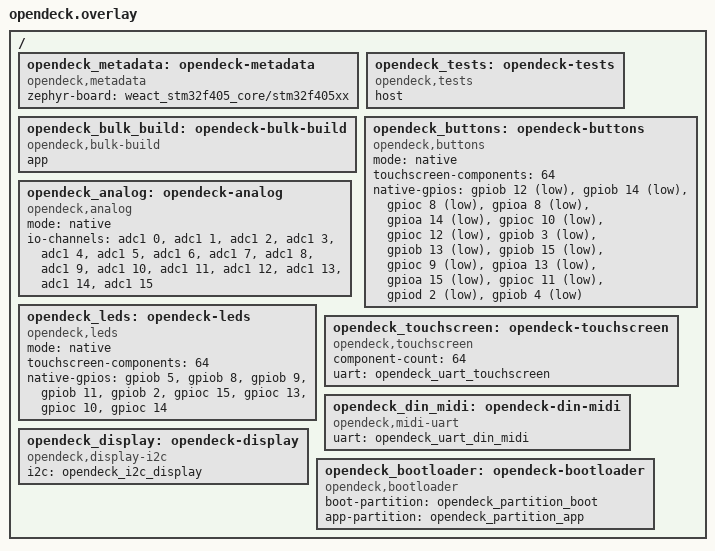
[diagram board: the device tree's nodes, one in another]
/ {
    opendeck_metadata: opendeck-metadata {
        compatible = "opendeck,metadata";
        zephyr-board = "weact_stm32f405_core/stm32f405xx";
    };

    opendeck_tests: opendeck-tests {
        compatible = "opendeck,tests";
        host;
    };

    opendeck_bulk_build: opendeck-bulk-build {
        compatible = "opendeck,bulk-build";
        app;
    };

    opendeck_buttons: opendeck-buttons {
        compatible = "opendeck,buttons";
        mode = "native";
        touchscreen-components = <64>;
        native-gpios =
            <&gpiob 12 (GPIO_PULL_UP | GPIO_ACTIVE_LOW)>,
            <&gpiob 14 (GPIO_PULL_UP | GPIO_ACTIVE_LOW)>,
            <&gpioc 8 (GPIO_PULL_UP | GPIO_ACTIVE_LOW)>,
            <&gpioa 8 (GPIO_PULL_UP | GPIO_ACTIVE_LOW)>,
            <&gpioa 14 (GPIO_PULL_UP | GPIO_ACTIVE_LOW)>,
            <&gpioc 10 (GPIO_PULL_UP | GPIO_ACTIVE_LOW)>,
            <&gpioc 12 (GPIO_PULL_UP | GPIO_ACTIVE_LOW)>,
            <&gpiob 3 (GPIO_PULL_UP | GPIO_ACTIVE_LOW)>,
            <&gpiob 13 (GPIO_PULL_UP | GPIO_ACTIVE_LOW)>,
            <&gpiob 15 (GPIO_PULL_UP | GPIO_ACTIVE_LOW)>,
            <&gpioc 9 (GPIO_PULL_UP | GPIO_ACTIVE_LOW)>,
            <&gpioa 13 (GPIO_PULL_UP | GPIO_ACTIVE_LOW)>,
            <&gpioa 15 (GPIO_PULL_UP | GPIO_ACTIVE_LOW)>,
            <&gpioc 11 (GPIO_PULL_UP | GPIO_ACTIVE_LOW)>,
            <&gpiod 2 (GPIO_PULL_UP | GPIO_ACTIVE_LOW)>,
            <&gpiob 4 (GPIO_PULL_UP | GPIO_ACTIVE_LOW)>;
    };

    opendeck_analog: opendeck-analog {
        compatible = "opendeck,analog";
        mode = "native";
        io-channels =
            <&adc1 0>,
            <&adc1 1>,
            <&adc1 2>,
            <&adc1 3>,
            <&adc1 4>,
            <&adc1 5>,
            <&adc1 6>,
            <&adc1 7>,
            <&adc1 8>,
            <&adc1 9>,
            <&adc1 10>,
            <&adc1 11>,
            <&adc1 12>,
            <&adc1 13>,
            <&adc1 14>,
            <&adc1 15>;
    };

    opendeck_leds: opendeck-leds {
        compatible = "opendeck,leds";
        mode = "native";
        touchscreen-components = <64>;
        native-gpios =
            <&gpiob 5 GPIO_ACTIVE_HIGH>,
            <&gpiob 8 GPIO_ACTIVE_HIGH>,
            <&gpiob 9 GPIO_ACTIVE_HIGH>,
            <&gpiob 11 GPIO_ACTIVE_HIGH>,
            <&gpiob 2 GPIO_ACTIVE_HIGH>,
            <&gpioc 15 GPIO_ACTIVE_HIGH>,
            <&gpioc 13 GPIO_ACTIVE_HIGH>,
            <&gpioc 10 GPIO_ACTIVE_HIGH>,
            <&gpioc 14 GPIO_ACTIVE_HIGH>;
    };

    opendeck_touchscreen: opendeck-touchscreen {
        compatible = "opendeck,touchscreen";
        component-count = <64>;
        uart = <&opendeck_uart_touchscreen>;
    };

    opendeck_din_midi: opendeck-din-midi {
        compatible = "opendeck,midi-uart";
        uart = <&opendeck_uart_din_midi>;
    };

    opendeck_display: opendeck-display {
        compatible = "opendeck,display-i2c";
        i2c = <&opendeck_i2c_display>;
    };

    opendeck_bootloader: opendeck-bootloader {
        compatible = "opendeck,bootloader";
        boot-partition = <&opendeck_partition_boot>;
        app-partition = <&opendeck_partition_app>;
    };
};
